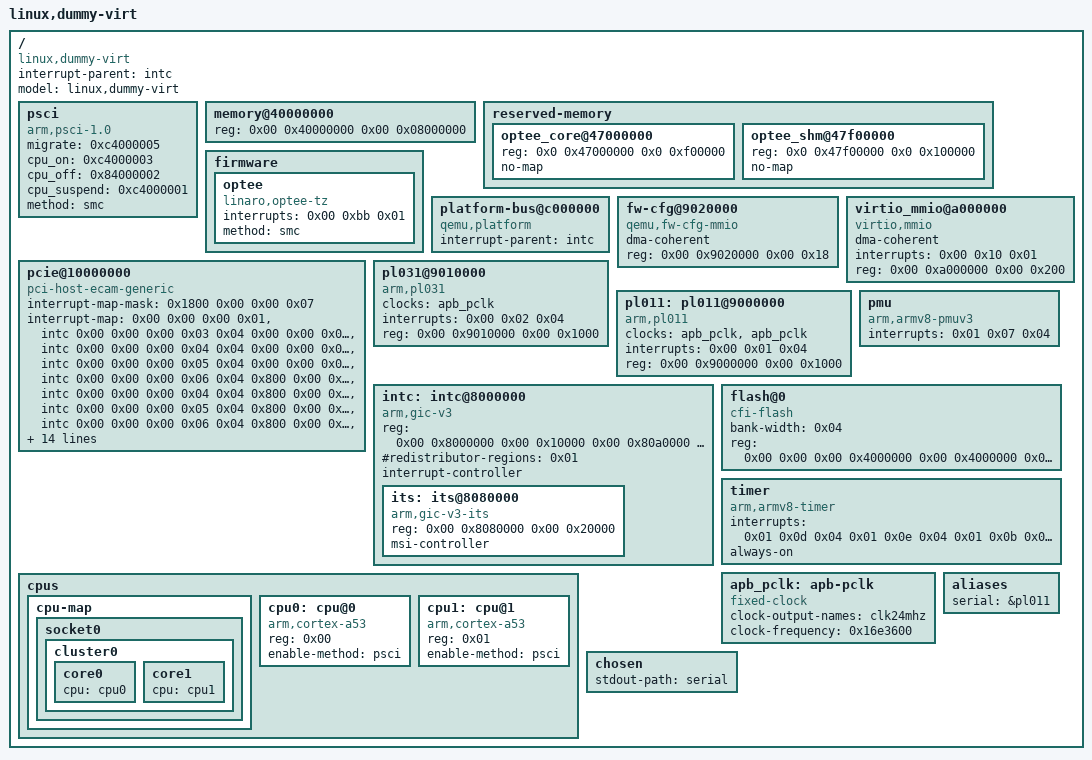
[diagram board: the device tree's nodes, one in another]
/dts-v1/;

/ {
	interrupt-parent = <&intc>;
	model = "linux,dummy-virt";
	#size-cells = <0x02>;
	#address-cells = <0x02>;
	compatible = "linux,dummy-virt";

	psci {
		migrate = <0xc4000005>;
		cpu_on = <0xc4000003>;
		cpu_off = <0x84000002>;
		cpu_suspend = <0xc4000001>;
		method = "smc";
		compatible = "arm,psci-1.0", "arm,psci-0.2", "arm,psci";
	};

	memory@40000000 {
		reg = <0x00 0x40000000 0x00 0x08000000>;
		device_type = "memory";
	};

	reserved-memory {
		#address-cells = <2>;
		#size-cells = <2>;
		ranges;

		optee_core@47000000 {
			reg = <0x0 0x47000000 0x0 0xf00000>;
			no-map;
		};
		optee_shm@47f00000 {
			reg = <0x0 0x47f00000 0x0 0x100000>;
			no-map;
		};
	};

	firmware {
		optee {
			interrupts = <0x00 0xbb 0x01>;
			method = "smc";
			compatible = "linaro,optee-tz";
		};
	};

	platform-bus@c000000 {
		interrupt-parent = <&intc>;
		ranges = <0x00 0x00 0xc000000 0x2000000>;
		#address-cells = <0x01>;
		#size-cells = <0x01>;
		compatible = "qemu,platform", "simple-bus";
	};

	fw-cfg@9020000 {
		dma-coherent;
		reg = <0x00 0x9020000 0x00 0x18>;
		compatible = "qemu,fw-cfg-mmio";
	};

	virtio_mmio@a000000 {
		dma-coherent;
		interrupts = <0x00 0x10 0x01>;
		reg = <0x00 0xa000000 0x00 0x200>;
		compatible = "virtio,mmio";
	};

	pcie@10000000 {
		interrupt-map-mask = <0x1800 0x00 0x00 0x07>;
		interrupt-map = <0x00 0x00 0x00 0x01 &intc 0x00 0x00 0x00 0x03 0x04
			0x00 0x00 0x00 0x02 &intc 0x00 0x00 0x00 0x04 0x04
			0x00 0x00 0x00 0x03 &intc 0x00 0x00 0x00 0x05 0x04
			0x00 0x00 0x00 0x04 &intc 0x00 0x00 0x00 0x06 0x04
			0x800 0x00 0x00 0x01 &intc 0x00 0x00 0x00 0x04 0x04
			0x800 0x00 0x00 0x02 &intc 0x00 0x00 0x00 0x05 0x04
			0x800 0x00 0x00 0x03 &intc 0x00 0x00 0x00 0x06 0x04
			0x800 0x00 0x00 0x04 &intc 0x00 0x00 0x00 0x03 0x04
			0x1000 0x00 0x00 0x01 &intc 0x00 0x00 0x00 0x05 0x04
			0x1000 0x00 0x00 0x02 &intc 0x00 0x00 0x00 0x06 0x04
			0x1000 0x00 0x00 0x03 &intc 0x00 0x00 0x00 0x03 0x04
			0x1000 0x00 0x00 0x04 &intc 0x00 0x00 0x00 0x04 0x04
			0x1800 0x00 0x00 0x01 &intc 0x00 0x00 0x00 0x06 0x04
			0x1800 0x00 0x00 0x02 &intc 0x00 0x00 0x00 0x03 0x04
			0x1800 0x00 0x00 0x03 &intc 0x00 0x00 0x00 0x04 0x04
			0x1800 0x00 0x00 0x04 &intc 0x00 0x00 0x00 0x05 0x04>;
		#interrupt-cells = <0x01>;
		ranges = <0x1000000 0x00 0x00 0x00 0x3eff0000 0x00 0x10000 0x2000000 0x00 0x10000000 0x00 0x10000000 0x00 0x2eff0000 0x3000000 0x80 0x00 0x80 0x00 0x80 0x00>;
		reg = <0x40 0x10000000 0x00 0x10000000>;
		msi-map = <0x00 &its 0x00 0x10000>;
		dma-coherent;
		bus-range = <0x00 0xff>;
		linux,pci-domain = <0x00>;
		#size-cells = <0x02>;
		#address-cells = <0x03>;
		device_type = "pci";
		compatible = "pci-host-ecam-generic";
	};

	pl031@9010000 {
		clock-names = "apb_pclk";
		clocks = <&apb_pclk>;
		interrupts = <0x00 0x02 0x04>;
		reg = <0x00 0x9010000 0x00 0x1000>;
		compatible = "arm,pl031", "arm,primecell";
	};

	pl011: pl011@9000000 {
		clock-names = "uartclk", "apb_pclk";
		clocks = <&apb_pclk &apb_pclk>;
		interrupts = <0x00 0x01 0x04>;
		reg = <0x00 0x9000000 0x00 0x1000>;
		compatible = "arm,pl011", "arm,primecell";
	};

	pmu {
		interrupts = <0x01 0x07 0x04>;
		compatible = "arm,armv8-pmuv3";
	};

	intc: intc@8000000 {
		reg = <0x00 0x8000000 0x00 0x10000 0x00 0x80a0000 0x00 0xf60000>;
		#redistributor-regions = <0x01>;
		compatible = "arm,gic-v3";
		ranges;
		#size-cells = <0x02>;
		#address-cells = <0x02>;
		interrupt-controller;
		#interrupt-cells = <0x03>;

		its: its@8080000 {
			reg = <0x00 0x8080000 0x00 0x20000>;
			#msi-cells = <0x01>;
			msi-controller;
			compatible = "arm,gic-v3-its";
		};
	};

	flash@0 {
		bank-width = <0x04>;
		reg = <0x00 0x00 0x00 0x4000000 0x00 0x4000000 0x00 0x4000000>;
		compatible = "cfi-flash";
	};

	cpus {
		#size-cells = <0x00>;
		#address-cells = <0x01>;

		cpu-map {

			socket0 {

				cluster0 {

					core0 {
						cpu = <&cpu0>;
					};

					core1 {
						cpu = <&cpu1>;
					};
				};
			};
		};

		cpu0: cpu@0 {
			reg = <0x00>;
			enable-method = "psci";
			compatible = "arm,cortex-a53";
			device_type = "cpu";
		};

		cpu1: cpu@1 {
			reg = <0x01>;
			enable-method = "psci";
			compatible = "arm,cortex-a53";
			device_type = "cpu";
		};
	};

	timer {
		interrupts = <0x01 0x0d 0x04 0x01 0x0e 0x04 0x01 0x0b 0x04 0x01 0x0a 0x04>;
		always-on;
		compatible = "arm,armv8-timer", "arm,armv7-timer";
	};

	apb_pclk: apb-pclk {
		clock-output-names = "clk24mhz";
		clock-frequency = <0x16e3600>;
		#clock-cells = <0x00>;
		compatible = "fixed-clock";
	};

	aliases {
		serial = &pl011;
	};

	chosen {
		stdout-path = "serial";
	};
};
